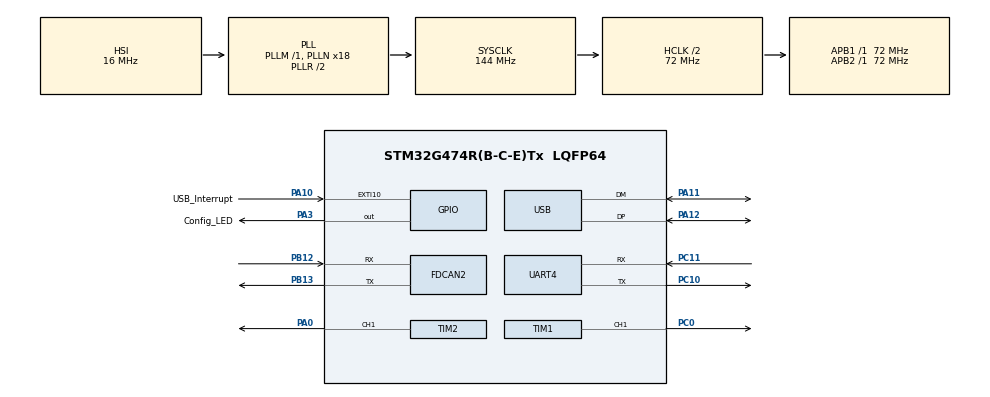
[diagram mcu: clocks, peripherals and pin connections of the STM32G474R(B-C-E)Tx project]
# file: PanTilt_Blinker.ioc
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FDCAN2.CalculateBaudRateNominal=1499999
FDCAN2.CalculateTimeBitNominal=666
FDCAN2.CalculateTimeQuantumNominal=222.22222222222223
Mcu.Family=STM32G4
Mcu.Name=STM32G474R(B-C-E)Tx
Mcu.Package=LQFP64
NVIC.PriorityGroup=NVIC_PRIORITYGROUP_4
PA0.Signal=S_TIM2_CH1
PA10.GPIO_Label=USB_Interrupt
PA10.Signal=GPXTI10
PA11.Mode=Device
PA11.Signal=USB_DM
PA12.Mode=Device
PA12.Signal=USB_DP
PA13.Mode=Trace_Asynchronous_SW
PA13.Signal=SYS_JTMS-SWDIO
PA14.Mode=Trace_Asynchronous_SW
PA14.Signal=SYS_JTCK-SWCLK
PA3.GPIO_Label=Config_LED
PA3.GPIO_PuPd=GPIO_PULLDOWN
PA3.Signal=GPIO_Output
PB12.Mode=FDCAN_Activate
PB12.Signal=FDCAN2_RX
PB13.Mode=FDCAN_Activate
PB13.Signal=FDCAN2_TX
PB3.Mode=Trace_Asynchronous_SW
PB3.Signal=SYS_JTDO-SWO
PC0.Signal=S_TIM1_CH1
PC10.Mode=Asynchronous
PC10.Signal=UART4_TX
PC11.Mode=Asynchronous
PC11.Signal=UART4_RX
ProjectManager.HeapSize=0x200
ProjectManager.StackSize=0x400
ProjectManager.TargetToolchain=CMake
RCC.ADC12Freq_Value=144000000
RCC.ADC345Freq_Value=144000000
RCC.AHBCLKDivider=RCC_SYSCLK_DIV2
RCC.AHBFreq_Value=72000000
RCC.APB1Freq_Value=72000000
RCC.APB1TimFreq_Value=72000000
RCC.APB2Freq_Value=72000000
RCC.APB2TimFreq_Value=72000000
RCC.CortexFreq_Value=72000000
RCC.EXTERNAL_CLOCK_VALUE=12288000
RCC.HCLKFreq_Value=72000000
RCC.HSE_VALUE=8000000
RCC.HSI48_VALUE=48000000
RCC.HSI_VALUE=16000000
RCC.LSE_VALUE=32768
RCC.PLLN=18
RCC.PLLQ=RCC_PLLQ_DIV6
RCC.SYSCLKFreq_VALUE=144000000
RCC.SYSCLKSource=RCC_SYSCLKSOURCE_PLLCLK
RCC.USBFreq_Value=48000000
RCC.VCOOutputFreq_Value=288000000
SH.S_TIM1_CH1.0=TIM1_CH1,PWM Generation1 CH1
SH.S_TIM2_CH1.0=TIM2_CH1,PWM Generation1 CH1
TIM1.Channel-PWM\ Generation1\ CH1=TIM_CHANNEL_1
TIM1.PeriodNoDither=1000-1
TIM1.Prescaler=1440-1
TIM2.Channel-PWM\ Generation1\ CH1=TIM_CHANNEL_1
TIM2.PeriodNoDither=65535
VP_SYS_VS_DBSignals.Mode=DisableDeadBatterySignals
VP_TIM1_VS_ClockSourceINT.Mode=Internal
board=custom

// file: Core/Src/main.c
/* USER CODE BEGIN Header */
/**
  ******************************************************************************
  * @file           : main.c
  * @brief          : Main program body
  ******************************************************************************
  * @attention
  *
  * Copyright (c) 2026 STMicroelectronics.
  * All rights reserved.
  *
  * This software is licensed under terms that can be found in the LICENSE file
  * in the root directory of this software component.
  * If no LICENSE file comes with this software, it is provided AS-IS.
  *
  ******************************************************************************
  */
/* USER CODE END Header */
#include "main.h"
#include "stm32g4xx_hal_def.h"

/* USER CODE BEGIN Includes */
#include <stdio.h>
#include <string.h>
/* USER CODE END Includes */

FDCAN_HandleTypeDef hfdcan2;

TIM_HandleTypeDef htim1;
TIM_HandleTypeDef htim2;

UART_HandleTypeDef huart4;

PCD_HandleTypeDef hpcd_USB_FS;

void SystemClock_Config(void);
static void MX_GPIO_Init(void);
static void MX_FDCAN2_Init(void);
static void MX_TIM1_Init(void);
static void MX_TIM2_Init(void);
static void MX_UART4_Init(void);
static void MX_USB_PCD_Init(void);

/* USER CODE BEGIN 0 */
int _write(int file, char *ptr, int len) {
  HAL_UART_Transmit(&huart4, (uint8_t*)ptr, len, HAL_MAX_DELAY);
  return len;
}

/* USER CODE END 0 */

int main(void)
{

  /* MCU Configuration--------------------------------------------------------*/

  /* Reset of all peripherals, Initializes the Flash interface and the Systick. */
  HAL_Init();

  /* Configure the system clock */
  SystemClock_Config();

  /* Initialize all configured peripherals */
  MX_GPIO_Init();
  MX_FDCAN2_Init();
  MX_TIM1_Init();
  MX_TIM2_Init();
  MX_UART4_Init();
  MX_USB_PCD_Init();
  /* USER CODE BEGIN 2 */
  printf("System started\r\n");

  // PWM Time!!
  HAL_TIM_PWM_Start(&htim1, TIM_CHANNEL_1);
  /* USER CODE END 2 */

  /* Infinite loop */
  while (1)
  {

    /* USER CODE BEGIN 3 */
    printf("Tim1Ch1: %ul\r\n", TIM1->CCR1);
    TIM1->CCR1 = 100;
    HAL_GPIO_TogglePin(Config_LED_GPIO_Port, Config_LED_Pin);
    HAL_Delay(3000);
    TIM1->CCR1 = 40;
    HAL_GPIO_TogglePin(Config_LED_GPIO_Port, Config_LED_Pin);
    HAL_Delay(3000);
  }
  /* USER CODE END 3 */
}

void SystemClock_Config(void)
{
  RCC_OscInitTypeDef RCC_OscInitStruct = {0};
  RCC_ClkInitTypeDef RCC_ClkInitStruct = {0};

  /** Configure the main internal regulator output voltage
  */
  HAL_PWREx_ControlVoltageScaling(PWR_REGULATOR_VOLTAGE_SCALE1);

  /** Initializes the RCC Oscillators according to the specified parameters
  * in the RCC_OscInitTypeDef structure.
  */
  RCC_OscInitStruct.OscillatorType = RCC_OSCILLATORTYPE_HSI;
  RCC_OscInitStruct.HSIState = RCC_HSI_ON;
  RCC_OscInitStruct.HSICalibrationValue = RCC_HSICALIBRATION_DEFAULT;
  RCC_OscInitStruct.PLL.PLLState = RCC_PLL_ON;
  RCC_OscInitStruct.PLL.PLLSource = RCC_PLLSOURCE_HSI;
  RCC_OscInitStruct.PLL.PLLM = RCC_PLLM_DIV1;
  RCC_OscInitStruct.PLL.PLLN = 18;
  RCC_OscInitStruct.PLL.PLLP = RCC_PLLP_DIV2;
  RCC_OscInitStruct.PLL.PLLQ = RCC_PLLQ_DIV6;
  RCC_OscInitStruct.PLL.PLLR = RCC_PLLR_DIV2;
  if (HAL_RCC_OscConfig(&RCC_OscInitStruct) != HAL_OK)
  {
    Error_Handler();
  }

  /** Initializes the CPU, AHB and APB buses clocks
  */
  RCC_ClkInitStruct.ClockType = RCC_CLOCKTYPE_HCLK|RCC_CLOCKTYPE_SYSCLK
                              |RCC_CLOCKTYPE_PCLK1|RCC_CLOCKTYPE_PCLK2;
  RCC_ClkInitStruct.SYSCLKSource = RCC_SYSCLKSOURCE_PLLCLK;
  RCC_ClkInitStruct.AHBCLKDivider = RCC_SYSCLK_DIV2;
  RCC_ClkInitStruct.APB1CLKDivider = RCC_HCLK_DIV1;
  RCC_ClkInitStruct.APB2CLKDivider = RCC_HCLK_DIV1;

  if (HAL_RCC_ClockConfig(&RCC_ClkInitStruct, FLASH_LATENCY_2) != HAL_OK)
  {
    Error_Handler();
  }
}

static void MX_FDCAN2_Init(void)
{

  hfdcan2.Instance = FDCAN2;
  hfdcan2.Init.ClockDivider = FDCAN_CLOCK_DIV1;
  hfdcan2.Init.FrameFormat = FDCAN_FRAME_CLASSIC;
  hfdcan2.Init.Mode = FDCAN_MODE_NORMAL;
  hfdcan2.Init.AutoRetransmission = DISABLE;
  hfdcan2.Init.TransmitPause = DISABLE;
  hfdcan2.Init.ProtocolException = DISABLE;
  hfdcan2.Init.NominalPrescaler = 16;
  hfdcan2.Init.NominalSyncJumpWidth = 1;
  hfdcan2.Init.NominalTimeSeg1 = 1;
  hfdcan2.Init.NominalTimeSeg2 = 1;
  hfdcan2.Init.DataPrescaler = 1;
  hfdcan2.Init.DataSyncJumpWidth = 1;
  hfdcan2.Init.DataTimeSeg1 = 1;
  hfdcan2.Init.DataTimeSeg2 = 1;
  hfdcan2.Init.StdFiltersNbr = 0;
  hfdcan2.Init.ExtFiltersNbr = 0;
  hfdcan2.Init.TxFifoQueueMode = FDCAN_TX_FIFO_OPERATION;
  if (HAL_FDCAN_Init(&hfdcan2) != HAL_OK)
  {
    Error_Handler();
  }

}

static void MX_TIM1_Init(void)
{

  TIM_ClockConfigTypeDef sClockSourceConfig = {0};
  TIM_MasterConfigTypeDef sMasterConfig = {0};
  TIM_OC_InitTypeDef sConfigOC = {0};
  TIM_BreakDeadTimeConfigTypeDef sBreakDeadTimeConfig = {0};

  htim1.Instance = TIM1;
  htim1.Init.Prescaler = 1440-1;
  htim1.Init.CounterMode = TIM_COUNTERMODE_UP;
  htim1.Init.Period = 999;
  htim1.Init.ClockDivision = TIM_CLOCKDIVISION_DIV1;
  htim1.Init.RepetitionCounter = 0;
  htim1.Init.AutoReloadPreload = TIM_AUTORELOAD_PRELOAD_DISABLE;
  if (HAL_TIM_Base_Init(&htim1) != HAL_OK)
  {
    Error_Handler();
  }
  sClockSourceConfig.ClockSource = TIM_CLOCKSOURCE_INTERNAL;
  if (HAL_TIM_ConfigClockSource(&htim1, &sClockSourceConfig) != HAL_OK)
  {
    Error_Handler();
  }
  if (HAL_TIM_PWM_Init(&htim1) != HAL_OK)
  {
    Error_Handler();
  }
  sMasterConfig.MasterOutputTrigger = TIM_TRGO_RESET;
  sMasterConfig.MasterOutputTrigger2 = TIM_TRGO2_RESET;
  sMasterConfig.MasterSlaveMode = TIM_MASTERSLAVEMODE_DISABLE;
  if (HAL_TIMEx_MasterConfigSynchronization(&htim1, &sMasterConfig) != HAL_OK)
  {
    Error_Handler();
  }
  sConfigOC.OCMode = TIM_OCMODE_PWM1;
  sConfigOC.Pulse = 0;
  sConfigOC.OCPolarity = TIM_OCPOLARITY_HIGH;
  sConfigOC.OCNPolarity = TIM_OCNPOLARITY_HIGH;
  sConfigOC.OCFastMode = TIM_OCFAST_DISABLE;
  sConfigOC.OCIdleState = TIM_OCIDLESTATE_RESET;
  sConfigOC.OCNIdleState = TIM_OCNIDLESTATE_RESET;
  if (HAL_TIM_PWM_ConfigChannel(&htim1, &sConfigOC, TIM_CHANNEL_1) != HAL_OK)
  {
    Error_Handler();
  }
  sBreakDeadTimeConfig.OffStateRunMode = TIM_OSSR_DISABLE;
  sBreakDeadTimeConfig.OffStateIDLEMode = TIM_OSSI_DISABLE;
  sBreakDeadTimeConfig.LockLevel = TIM_LOCKLEVEL_OFF;
  sBreakDeadTimeConfig.DeadTime = 0;
  sBreakDeadTimeConfig.BreakState = TIM_BREAK_DISABLE;
  sBreakDeadTimeConfig.BreakPolarity = TIM_BREAKPOLARITY_HIGH;
  sBreakDeadTimeConfig.BreakFilter = 0;
  sBreakDeadTimeConfig.BreakAFMode = TIM_BREAK_AFMODE_INPUT;
  sBreakDeadTimeConfig.Break2State = TIM_BREAK2_DISABLE;
  sBreakDeadTimeConfig.Break2Polarity = TIM_BREAK2POLARITY_HIGH;
  sBreakDeadTimeConfig.Break2Filter = 0;
  sBreakDeadTimeConfig.Break2AFMode = TIM_BREAK_AFMODE_INPUT;
  sBreakDeadTimeConfig.AutomaticOutput = TIM_AUTOMATICOUTPUT_DISABLE;
  if (HAL_TIMEx_ConfigBreakDeadTime(&htim1, &sBreakDeadTimeConfig) != HAL_OK)
  {
    Error_Handler();
  }
  HAL_TIM_MspPostInit(&htim1);

}

static void MX_TIM2_Init(void)
{

  TIM_MasterConfigTypeDef sMasterConfig = {0};
  TIM_OC_InitTypeDef sConfigOC = {0};

  htim2.Instance = TIM2;
  htim2.Init.Prescaler = 0;
  htim2.Init.CounterMode = TIM_COUNTERMODE_UP;
  htim2.Init.Period = 65535;
  htim2.Init.ClockDivision = TIM_CLOCKDIVISION_DIV1;
  htim2.Init.AutoReloadPreload = TIM_AUTORELOAD_PRELOAD_DISABLE;
  if (HAL_TIM_PWM_Init(&htim2) != HAL_OK)
  {
    Error_Handler();
  }
  sMasterConfig.MasterOutputTrigger = TIM_TRGO_RESET;
  sMasterConfig.MasterSlaveMode = TIM_MASTERSLAVEMODE_DISABLE;
  if (HAL_TIMEx_MasterConfigSynchronization(&htim2, &sMasterConfig) != HAL_OK)
  {
    Error_Handler();
  }
  sConfigOC.OCMode = TIM_OCMODE_PWM1;
  sConfigOC.Pulse = 0;
  sConfigOC.OCPolarity = TIM_OCPOLARITY_HIGH;
  sConfigOC.OCFastMode = TIM_OCFAST_DISABLE;
  if (HAL_TIM_PWM_ConfigChannel(&htim2, &sConfigOC, TIM_CHANNEL_1) != HAL_OK)
  {
    Error_Handler();
  }
  HAL_TIM_MspPostInit(&htim2);

}

static void MX_UART4_Init(void)
{

  huart4.Instance = UART4;
  huart4.Init.BaudRate = 115200;
  huart4.Init.WordLength = UART_WORDLENGTH_8B;
  huart4.Init.StopBits = UART_STOPBITS_1;
  huart4.Init.Parity = UART_PARITY_NONE;
  huart4.Init.Mode = UART_MODE_TX_RX;
  huart4.Init.HwFlowCtl = UART_HWCONTROL_NONE;
  huart4.Init.OverSampling = UART_OVERSAMPLING_16;
  huart4.Init.OneBitSampling = UART_ONE_BIT_SAMPLE_DISABLE;
  huart4.Init.ClockPrescaler = UART_PRESCALER_DIV1;
  huart4.AdvancedInit.AdvFeatureInit = UART_ADVFEATURE_NO_INIT;
  if (HAL_UART_Init(&huart4) != HAL_OK)
  {
    Error_Handler();
  }
  if (HAL_UARTEx_SetTxFifoThreshold(&huart4, UART_TXFIFO_THRESHOLD_1_8) != HAL_OK)
  {
    Error_Handler();
  }
  if (HAL_UARTEx_SetRxFifoThreshold(&huart4, UART_RXFIFO_THRESHOLD_1_8) != HAL_OK)
  {
    Error_Handler();
  }
  if (HAL_UARTEx_DisableFifoMode(&huart4) != HAL_OK)
  {
    Error_Handler();
  }

}

static void MX_USB_PCD_Init(void)
{

  hpcd_USB_FS.Instance = USB;
  hpcd_USB_FS.Init.dev_endpoints = 8;
  hpcd_USB_FS.Init.speed = PCD_SPEED_FULL;
  hpcd_USB_FS.Init.phy_itface = PCD_PHY_EMBEDDED;
  hpcd_USB_FS.Init.Sof_enable = DISABLE;
  hpcd_USB_FS.Init.low_power_enable = DISABLE;
  hpcd_USB_FS.Init.lpm_enable = DISABLE;
  hpcd_USB_FS.Init.battery_charging_enable = DISABLE;
  if (HAL_PCD_Init(&hpcd_USB_FS) != HAL_OK)
  {
    Error_Handler();
  }

}

static void MX_GPIO_Init(void)
{
  GPIO_InitTypeDef GPIO_InitStruct = {0};

  /* GPIO Ports Clock Enable */
  __HAL_RCC_GPIOC_CLK_ENABLE();
  __HAL_RCC_GPIOA_CLK_ENABLE();
  __HAL_RCC_GPIOB_CLK_ENABLE();

  /*Configure GPIO pin Output Level */
  HAL_GPIO_WritePin(Config_LED_GPIO_Port, Config_LED_Pin, GPIO_PIN_RESET);

  /*Configure GPIO pin : Config_LED_Pin */
  GPIO_InitStruct.Pin = Config_LED_Pin;
  GPIO_InitStruct.Mode = GPIO_MODE_OUTPUT_PP;
  GPIO_InitStruct.Pull = GPIO_PULLDOWN;
  GPIO_InitStruct.Speed = GPIO_SPEED_FREQ_LOW;
  HAL_GPIO_Init(Config_LED_GPIO_Port, &GPIO_InitStruct);

  /*Configure GPIO pin : USB_Interrupt_Pin */
  GPIO_InitStruct.Pin = USB_Interrupt_Pin;
  GPIO_InitStruct.Mode = GPIO_MODE_IT_RISING;
  GPIO_InitStruct.Pull = GPIO_NOPULL;
  HAL_GPIO_Init(USB_Interrupt_GPIO_Port, &GPIO_InitStruct);

}

void Error_Handler(void)
{
  __disable_irq();
  while (1)
  {
  }
}
